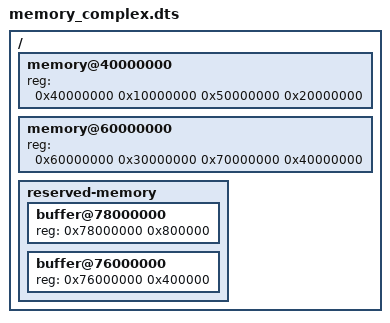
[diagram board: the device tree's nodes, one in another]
// Copyright 2021 The Fuchsia Authors. All rights reserved.
// Use of this source code is governed by a BSD-style license that can be
// found in the LICENSE file.

/dts-v1/;

/memreserve/ 0x12340000 0x2000;
/memreserve/ 0x56780000 0x3000;
/memreserve/ 0x7fffffff12340000 0x400000000;
/memreserve/ 0x00ffffff56780000 0x500000000;

/ {
    #address-cells = <1>;
    #size-cells = <1>;
    memory@40000000 {
        device_type = "memory";
        reg = <0x40000000 0x10000000
            0x50000000 0x20000000>;
    };
    memory@60000000 {
        device_type = "memory";
        reg = <0x60000000 0x30000000
            0x70000000 0x40000000>;
    };
     reserved-memory {
        #address-cells = <1>;
        #size-cells = <1>;
        ranges;
        buffer@78000000 {
            reg = <0x78000000 0x800000>;
        };

        buffer@76000000 {
            reg = <0x76000000 0x400000>;
        };
    };
};
